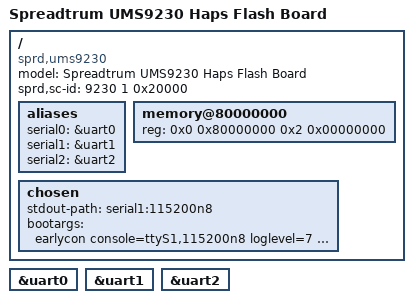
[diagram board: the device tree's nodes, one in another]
// SPDX-License-Identifier: GPL-2.0-only
/*
 * Unisoc Qogirl6 platform DTS file
 *
 * Copyright (C) 2020, Unisoc Inc.
 */

/dts-v1/;

#include "ums9230-haps-flash.dtsi"
#include "ums9230-haps-flash-mach.dtsi"

/ {
	model = "Spreadtrum UMS9230 Haps Flash Board";

	compatible = "sprd,ums9230";

	sprd,sc-id = <9230 1 0x20000>;

	aliases {
		serial0 = &uart0;
		serial1 = &uart1;
		serial2 = &uart2;
	};

	memory@80000000 {
		device_type = "memory";
		reg = <0x0 0x80000000 0x2 0x00000000>;
	};

	chosen {
		stdout-path = "serial1:115200n8";
		bootargs = "earlycon console=ttyS1,115200n8 loglevel=7 init=/init root=/dev/ram0 rw androidboot.hardware=ums9230_haps androidboot.dtbo_idx=0 printk.devkmsg=on androidboot.boot_devices=soc/soc:apb/201d0000.sdio androidboot.selinux=permissive";
	};
};

&uart0 {
	status = "okay";
};

&uart1 {
	status = "okay";
};

&uart2 {
	status = "okay";
};
